# BL602 register map
Vendor: bouffalolab; Series: WiFi BT
Registers are 32-bit, read-write, reset 0x0 unless marked. A register's access mark holds for its fields unless they carry their own. Offsets are from the block's base; [hi:lo] are bit positions; {n}, {i} and the like mark numbered series; 'fields as' and 'values as' point back to an identical list; <NAME> marks a mode.

## GLB — Global register
Base 0x40000000
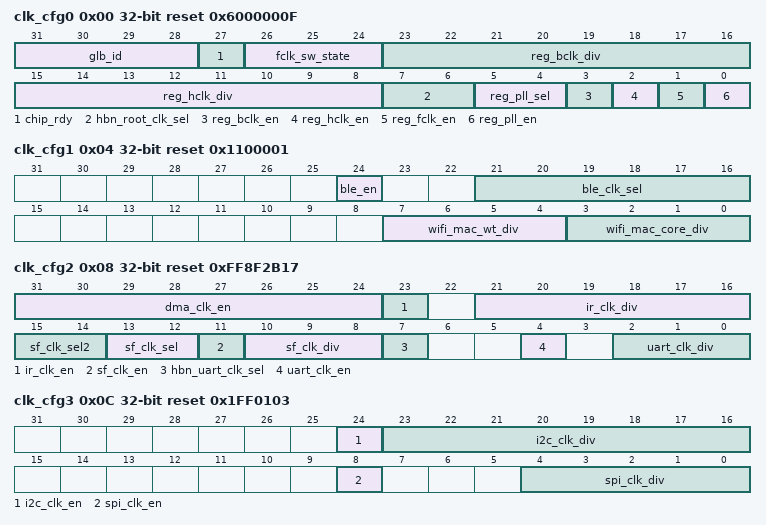
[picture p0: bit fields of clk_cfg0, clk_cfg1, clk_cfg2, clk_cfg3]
0x00 clk_cfg0 reset 0x6000000F — Clock configuration for processor and bus
  [31:28] glb_id ro
  [27] chip_rdy ro
  [26:24] fclk_sw_state ro
  [23:16] reg_bclk_div — Base clock divider
  [15:8] reg_hclk_div — MCU clock divider
  [7:6] hbn_root_clk_sel ro
  [5:4] reg_pll_sel — PLL clock selection (0: 48MHz, 1: 120MHz, 2: 160MHz and 3: 192MHz)
  [3] reg_bclk_en — Base clock enable
  [2] reg_hclk_en — MCU clock enable
  [1] reg_fclk_en
  [0] reg_pll_en — PLL enable
0x04 clk_cfg1 reset 0x1100001
  [24] ble_en — Bluetooth clock enable
  [21:16] ble_clk_sel
  [7:4] wifi_mac_wt_div — WiFi encryption clock divider
  [3:0] wifi_mac_core_div — WiFi core clock divider (0: 80MHz, 1: 40MHz)
0x08 clk_cfg2 reset 0xFF8F2B17 — Clock configuration for UART and Flash
  [31:24] dma_clk_en, [23] ir_clk_en, [21:16] ir_clk_div, [15:14] sf_clk_sel2, [13:12] sf_clk_sel, [11] sf_clk_en, [10:8] sf_clk_div, [7] hbn_uart_clk_sel ro, [4] uart_clk_en, [2:0] uart_clk_div
0x0C clk_cfg3 reset 0x1FF0103 — Clock configuration for I2C and SPI
  [24] i2c_clk_en, [23:16] i2c_clk_div, [8] spi_clk_en, [4:0] spi_clk_div
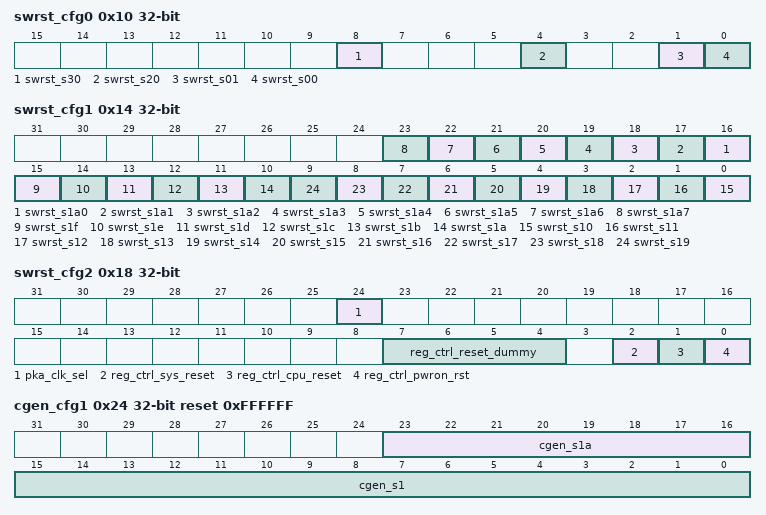
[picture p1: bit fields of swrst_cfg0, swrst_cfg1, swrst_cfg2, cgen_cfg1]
0x10 swrst_cfg0
  [8] swrst_s30, [4] swrst_s20, [1] swrst_s01, [0] swrst_s00
0x14 swrst_cfg1
  [n+16] swrst_s1a{n} (n=0..7), [15] swrst_s1f, [14] swrst_s1e, [13] swrst_s1d, [12] swrst_s1c, [11] swrst_s1b, [10] swrst_s1a, [n-10] swrst_s{n} (n=10..19)
0x18 swrst_cfg2
  [24] pka_clk_sel, [7:4] reg_ctrl_reset_dummy, [2] reg_ctrl_sys_reset, [1] reg_ctrl_cpu_reset, [0] reg_ctrl_pwron_rst
0x1C swrst_cfg3
0x20 cgen_cfg0 reset 0xFF
  [7:0] cgen_m
0x24 cgen_cfg1 reset 0xFFFFFF
  [23:16] cgen_s1a, [15:0] cgen_s1
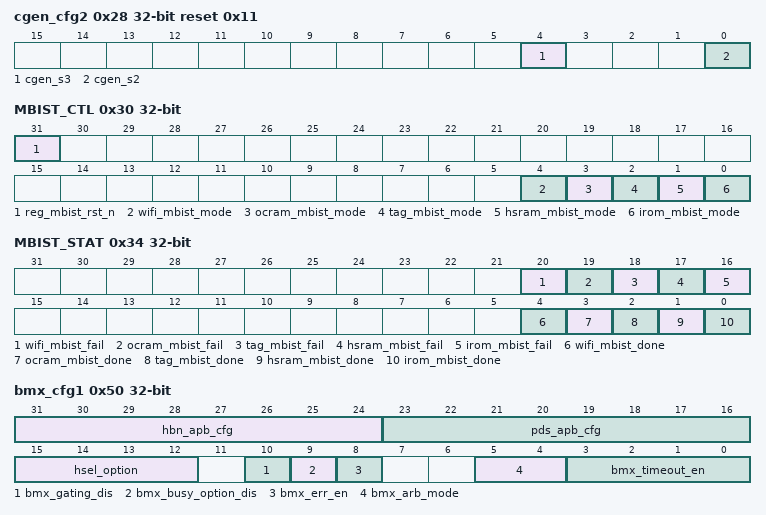
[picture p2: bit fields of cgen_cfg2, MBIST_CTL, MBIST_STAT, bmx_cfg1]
0x28 cgen_cfg2 reset 0x11
  [4] cgen_s3, [0] cgen_s2
0x2C cgen_cfg3
0x30 MBIST_CTL
  [31] reg_mbist_rst_n, [4] wifi_mbist_mode, [3] ocram_mbist_mode, [2] tag_mbist_mode, [1] hsram_mbist_mode, [0] irom_mbist_mode
0x34 MBIST_STAT ro
  [20] wifi_mbist_fail, [19] ocram_mbist_fail, [18] tag_mbist_fail, [17] hsram_mbist_fail, [16] irom_mbist_fail, [4] wifi_mbist_done, [3] ocram_mbist_done, [2] tag_mbist_done, [1] hsram_mbist_done, [0] irom_mbist_done
0x50 bmx_cfg1
  [31:24] hbn_apb_cfg, [23:16] pds_apb_cfg, [15:12] hsel_option, [10] bmx_gating_dis, [9] bmx_busy_option_dis, [8] bmx_err_en, [5:4] bmx_arb_mode, [3:0] bmx_timeout_en
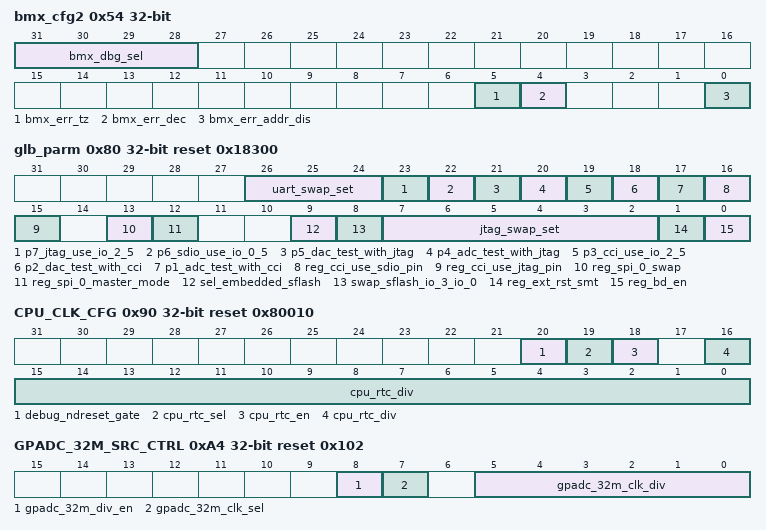
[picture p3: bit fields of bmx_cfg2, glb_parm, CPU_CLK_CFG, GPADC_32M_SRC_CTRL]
0x54 bmx_cfg2
  [31:28] bmx_dbg_sel
  [5] bmx_err_tz ro
  [4] bmx_err_dec ro
  [0] bmx_err_addr_dis — BMX address monitor disable
0x58 bmx_err_addr ro
0x5C bmx_dbg_out ro
{0x60+4i} rsv{i} (i=0..3)
0x70 sram_ret
  [31:0] reg_sram_ret
0x74 sram_slp
  [31:0] reg_sram_slp
0x78 sram_parm reset 0xC0C0C0C
  [31:0] reg_sram_parm
0x7C seam_misc reset 0x3
  [3:0] em_sel
0x80 glb_parm reset 0x18300
  [26:24] uart_swap_set, [23] p7_jtag_use_io_2_5, [22] p6_sdio_use_io_0_5, [21] p5_dac_test_with_jtag, [20] p4_adc_test_with_jtag, [19] p3_cci_use_io_2_5, [18] p2_dac_test_with_cci, [17] p1_adc_test_with_cci, [16] reg_cci_use_sdio_pin, [15] reg_cci_use_jtag_pin, [13] reg_spi_0_swap, [12] reg_spi_0_master_mode, [9] sel_embedded_sflash, [8] swap_sflash_io_3_io_0, [7:2] jtag_swap_set, [1] reg_ext_rst_smt, [0] reg_bd_en
0x90 CPU_CLK_CFG reset 0x80010
  [20] debug_ndreset_gate, [19] cpu_rtc_sel, [18] cpu_rtc_en, [16:0] cpu_rtc_div
0xA4 GPADC_32M_SRC_CTRL reset 0x102 — Clock configuration for GPADC
  [8] gpadc_32m_div_en, [7] gpadc_32m_clk_sel, [5:0] gpadc_32m_clk_div
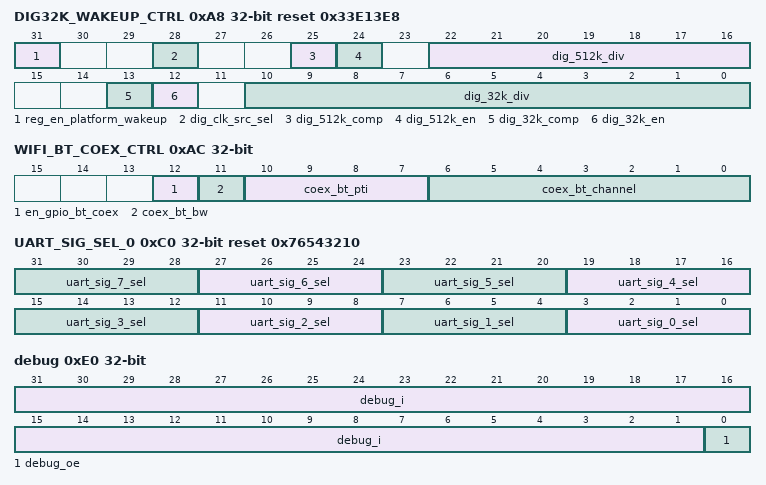
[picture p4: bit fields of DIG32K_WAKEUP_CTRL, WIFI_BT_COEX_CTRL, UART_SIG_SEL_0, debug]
0xA8 DIG32K_WAKEUP_CTRL reset 0x33E13E8
  [31] reg_en_platform_wakeup, [28] dig_clk_src_sel, [25] dig_512k_comp, [24] dig_512k_en, [22:16] dig_512k_div, [13] dig_32k_comp, [12] dig_32k_en, [10:0] dig_32k_div
0xAC WIFI_BT_COEX_CTRL
  [12] en_gpio_bt_coex, [11] coex_bt_bw, [10:7] coex_bt_pti, [6:0] coex_bt_channel
0xC0 UART_SIG_SEL_0 reset 0x76543210
  [4n+3:4n] uart_sig_{n}_sel (n=0..7)
0xD0 DBG_SEL_LL
  [31:0] reg_dbg_ll_ctrl
0xD4 DBG_SEL_LH
  [31:0] reg_dbg_lh_ctrl
0xD8 DBG_SEL_HL
  [31:0] reg_dbg_hl_ctrl
0xDC DBG_SEL_HH
  [31:0] reg_dbg_hh_ctrl
0xE0 debug
  [31:1] debug_i ro, [0] debug_oe
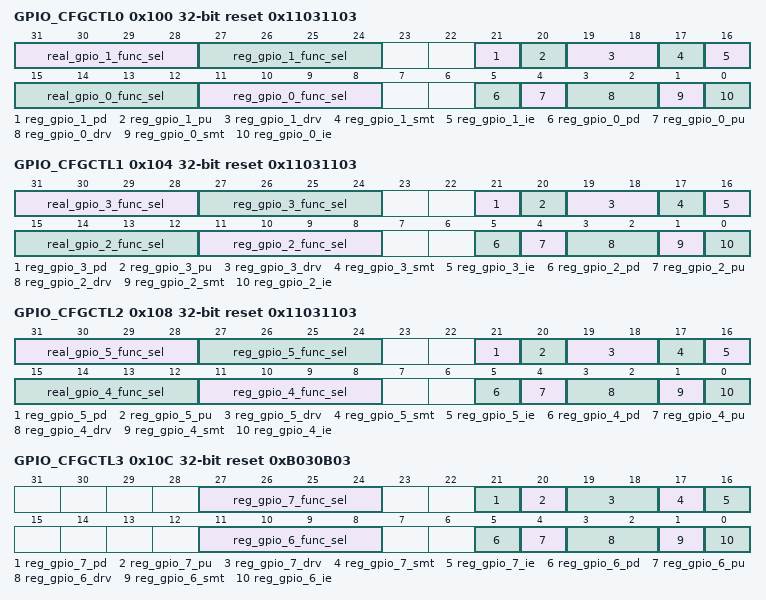
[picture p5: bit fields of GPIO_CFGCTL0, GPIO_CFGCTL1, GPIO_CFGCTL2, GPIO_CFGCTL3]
0x100 GPIO_CFGCTL0 reset 0x11031103 — GPIO0, GPIO1 configuration
  [31:28] real_gpio_1_func_sel ro
    0=GLB_GPIO_REAL_MODE_REG (Function select is reg_gpio_1_func_sel); 1=GLB_GPIO_REAL_MODE_SDIO; 12=GLB_GPIO_REAL_MODE_RF; 14=GLB_GPIO_REAL_MODE_JTAG; 15=GLB_GPIO_REAL_MODE_CCI
  [27:24] reg_gpio_1_func_sel — Function select for GPIO1.
    1=SDIO_CMD; 2=SF_D2; 4=SPI_MOSI_SPI_MISO; 6=I2C_SDA; 7=UART_SIG1; 8=PWM_CH1; 9=FEM_GPIO_1; 10=ATEST_IP; 11=SWGPIO_1; 14=E21_TDI
  [21] reg_gpio_1_pd — Pull Down Resistor for GPIO1.
    0=disabled; 1=enabled
  [20] reg_gpio_1_pu — Pull Up Resistor for GPIO1.
    0=disabled; 1=enabled
  [19:18] reg_gpio_1_drv — Driving control enabled for GPIO1.
    0=disabled; 1=enabled
  [17] reg_gpio_1_smt — Schmitt trigger enabled for GPIO1.
    0=disabled; 1=enabled
  [16] reg_gpio_1_ie — Input enable for GPIO1.
    0=disabled; 1=enabled
  [15:12] real_gpio_0_func_sel ro
    0=GLB_GPIO_REAL_MODE_REG (Function select is reg_gpio_0_func_sel); 1=GLB_GPIO_REAL_MODE_SDIO; 12=GLB_GPIO_REAL_MODE_RF; 14=GLB_GPIO_REAL_MODE_JTAG; 15=GLB_GPIO_REAL_MODE_CCI
  [11:8] reg_gpio_0_func_sel — Function select for GPIO0.
    1=SDIO_CLK; 2=SF_D1; 4=SPI_MOSI_SPI_MISO; 6=I2C_SCL; 7=UART_SIG0; 8=PWM_CH0; 9=FEM_GPIO_0; 10=ATEST_IN; 11=SWGPIO_0; 14=E21_TMS
  [5] reg_gpio_0_pd — Pull Down Resistor for GPIO0.
    0=disabled; 1=enabled
  [4] reg_gpio_0_pu — Pull Up Resistor for GPIO0.
    0=disabled; 1=enabled
  [3:2] reg_gpio_0_drv — Driving control for GPIO0.
    0=disabled; 1=enabled
  [1] reg_gpio_0_smt — Schmitt trigger enabled for GPIO0.
    0=disabled; 1=enabled
  [0] reg_gpio_0_ie — GPIO0 input enable.
    0=disabled; 1=enabled
0x104 GPIO_CFGCTL1 reset 0x11031103 — GPIO2, GPIO3 configuration
  [31:28] real_gpio_3_func_sel ro
    0=GLB_GPIO_REAL_MODE_REG (Function select is reg_gpio_3_func_sel); 1=GLB_GPIO_REAL_MODE_SDIO; 12=GLB_GPIO_REAL_MODE_RF; 14=GLB_GPIO_REAL_MODE_JTAG; 15=GLB_GPIO_REAL_MODE_CCI
  [27:24] reg_gpio_3_func_sel — Function select for GPIO3.
    1=SDIO_DAT1; 4=SPI_SCLK; 6=I2C_SDA; 7=UART_SIG3; 8=PWM_CH3; 9=FEM_GPIO_3; 10=ATEST_QP; 11=SWGPIO_3; 14=E21_TDO
  [21] reg_gpio_3_pd — Pull Down Resistor for GPIO3.
    0=disabled; 1=enabled
  [20] reg_gpio_3_pu — Pull Up Resistor for GPIO3.
    0=disabled; 1=enabled
  [19:18] reg_gpio_3_drv — Driving control enabled for GPIO3.
    0=disabled; 1=enabled
  [17] reg_gpio_3_smt — Schmitt trigger enabled for GPIO3.
    0=disabled; 1=enabled
  [16] reg_gpio_3_ie — Input enable for GPIO3.
    0=disabled; 1=enabled
  [15:12] real_gpio_2_func_sel ro
    0=GLB_GPIO_REAL_MODE_REG (Function select is reg_gpio_2_func_sel); 1=GLB_GPIO_REAL_MODE_SDIO; 12=GLB_GPIO_REAL_MODE_RF; 14=GLB_GPIO_REAL_MODE_JTAG; 15=GLB_GPIO_REAL_MODE_CCI
  [11:8] reg_gpio_2_func_sel — Function select for GPIO2.
    1=SDIO_DAT0; 2=SF_D3; 4=SPI_SS; 6=I2C_SCL; 7=UART_SIG2; 8=PWM_CH2; 9=FEM_GPIO_2; 10=ATEST_QN; 11=SWGPIO_2; 14=E21_TCK
  [5] reg_gpio_2_pd — Pull Down Resistor for GPIO2.
    0=disabled; 1=enabled
  [4] reg_gpio_2_pu — Pull Up Resistor for GPIO2.
    0=disabled; 1=enabled
  [3:2] reg_gpio_2_drv — Driving control enabled for GPIO2.
    0=disabled; 1=enabled
  [1] reg_gpio_2_smt — Schmitt trigger enabled for GPIO2.
    0=disabled; 1=enabled
  [0] reg_gpio_2_ie — Input enable for GPIO2.
    0=disabled; 1=enabled
0x108 GPIO_CFGCTL2 reset 0x11031103 — GPIO4, GPIO5 configuration
  [31:28] real_gpio_5_func_sel ro
    0=GLB_GPIO_REAL_MODE_REG (Function select is reg_gpio_5_func_sel); 1=GLB_GPIO_REAL_MODE_SDIO; 12=GLB_GPIO_REAL_MODE_RF; 14=GLB_GPIO_REAL_MODE_JTAG; 15=GLB_GPIO_REAL_MODE_CCI
  [27:24] reg_gpio_5_func_sel — Function select for GPIO5.
    1=SDIO_DAT3; 4=SPI_MOSI_SPI_MISO; 6=I2C_SDA; 7=UART_SIG5; 8=PWM_CH0; 9=FEM_GPIO_1; 10=GPIP_CH4; 11=SWGPIO_5; 14=E21_TDI
  [21] reg_gpio_5_pd — Pull Down Resistor for GPIO5.
    0=disabled; 1=enabled
  [20] reg_gpio_5_pu — Pull Up Resistor for GPIO5.
    0=disabled; 1=enabled
  [19:18] reg_gpio_5_drv — Driving control enabled for GPIO5.
    0=disabled; 1=enabled
  [17] reg_gpio_5_smt — Schmitt trigger enabled for GPIO5.
    0=disabled; 1=enabled
  [16] reg_gpio_5_ie — Input enable for GPIO5.
    0=disabled; 1=enabled
  [15:12] real_gpio_4_func_sel ro
    0=GLB_GPIO_REAL_MODE_REG (Function select is reg_gpio_4_func_sel); 1=GLB_GPIO_REAL_MODE_SDIO; 12=GLB_GPIO_REAL_MODE_RF; 14=GLB_GPIO_REAL_MODE_JTAG; 15=GLB_GPIO_REAL_MODE_CCI
  [11:8] reg_gpio_4_func_sel — Function select for GPIO4.
    1=SDIO_DAT2; 4=SPI_MISO_SPI_MOSI; 6=I2C_SCL; 7=UART_SIG4; 8=PWM_CH4; 9=FEM_GPIO_0; 10=GPIP_CH1; 11=SWGPIO_4; 14=E21_TMS
  [5] reg_gpio_4_pd — Pull Down Resistor for GPIO4.
    0=disabled; 1=enabled
  [4] reg_gpio_4_pu — Pull Up Resistor for GPIO4.
    0=disabled; 1=enabled
  [3:2] reg_gpio_4_drv — Driving control enabled for GPIO4.
    0=disabled; 1=enabled
  [1] reg_gpio_4_smt — Schmitt trigger enabled for GPIO4.
    0=disabled; 1=enabled
  [0] reg_gpio_4_ie — Input enable for GPIO4.
    0=disabled; 1=enabled
0x10C GPIO_CFGCTL3 reset 0xB030B03 — GPIO6, GPIO7 configuration
  [27:24] reg_gpio_7_func_sel — Function select for GPIO7.
    4=SPI_SCLK; 6=I2C_SDA; 7=UART_SIG7; 8=PWM_CH2; 9=FEM_GPIO_3; 11=SWGPIO_7; 14=E21_TDO
  [21] reg_gpio_7_pd — Pull Down Resistor for GPIO7.
    0=disabled; 1=enabled
  [20] reg_gpio_7_pu — Pull Up Resistor for GPIO7.
    0=disabled; 1=enabled
  [19:18] reg_gpio_7_drv — Driving control enabled for GPIO7.
    0=disabled; 1=enabled
  [17] reg_gpio_7_smt — Schmitt trigger enabled for GPIO7.
    0=disabled; 1=enabled
  [16] reg_gpio_7_ie — Input enable for GPIO7.
    0=disabled; 1=enabled
  [11:8] reg_gpio_6_func_sel — Function select for GPIO6.
    4=SPI_SS; 6=I2C_SCL; 7=UART_SIG6; 8=PWM_CH1; 9=FEM_GPIO_2; 10=GPIP_CH5; 11=SWGPIO_6; 14=E21_TCK
  [5] reg_gpio_6_pd — Pull Down Resistor for GPIO6.
    0=disabled; 1=enabled
  [4] reg_gpio_6_pu — Pull Up Resistor for GPIO6.
    0=disabled; 1=enabled
  [3:2] reg_gpio_6_drv — Driving control enabled for GPIO6.
    0=disabled; 1=enabled
  [1] reg_gpio_6_smt — Schmitt trigger enabled for GPIO6.
    0=disabled; 1=enabled
  [0] reg_gpio_6_ie — Input enable for GPIO6.
    0=disabled; 1=enabled
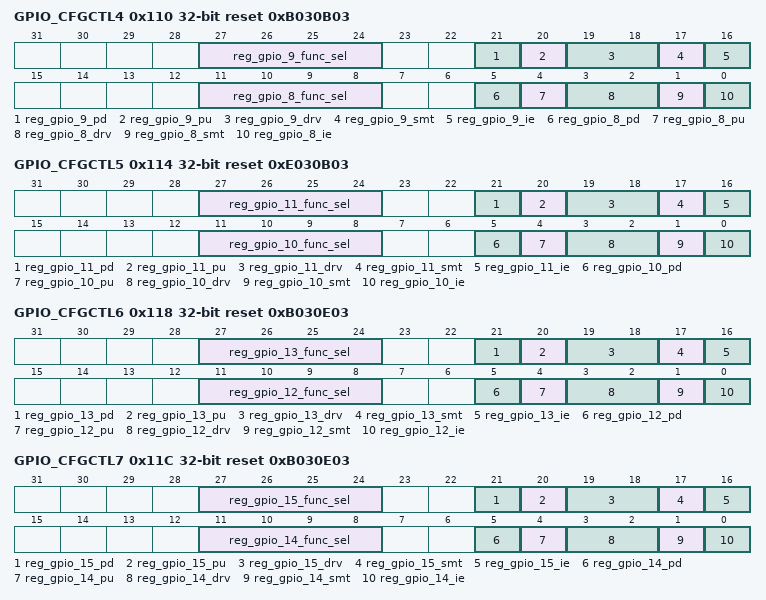
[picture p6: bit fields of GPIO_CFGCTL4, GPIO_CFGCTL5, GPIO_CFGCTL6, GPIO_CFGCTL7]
0x110 GPIO_CFGCTL4 reset 0xB030B03 — GPIO8, GPIO9 configuration
  [27:24] reg_gpio_9_func_sel — Function select for GPIO9.
    4=SPI_MOSI_SPI_MISO; 6=I2C_SDA; 7=UART_SIG1; 8=PWM_CH4; 9=FEM_GPIO_1; 10=GPIP_CH6_GPIP_CH7; 11=SWGPIO_9; 14=E21_TDI
  [21] reg_gpio_9_pd — Pull Down Resistor for GPIO9.
    0=disabled; 1=enabled
  [20] reg_gpio_9_pu — Pull Up Resistor for GPIO9.
    0=disabled; 1=enabled
  [19:18] reg_gpio_9_drv — Driving control enabled for GPIO9.
    0=disabled; 1=enabled
  [17] reg_gpio_9_smt — Schmitt trigger enabled for GPIO9.
    0=disabled; 1=enabled
  [16] reg_gpio_9_ie — Input enable for GPIO9.
    0=disabled; 1=enabled
  [11:8] reg_gpio_8_func_sel — Function select for GPIO8.
    4=SPI_MISO_SPI_MOSI; 6=I2C_SCL; 7=UART_SIG0; 8=PWM_CH3; 9=FEM_GPIO_0; 11=SWGPIO_8; 14=E21_TMS
  [5] reg_gpio_8_pd — Pull Down Resistor for GPIO8.
    0=disabled; 1=enabled
  [4] reg_gpio_8_pu — Pull Up Resistor for GPIO8.
    0=disabled; 1=enabled
  [3:2] reg_gpio_8_drv — Driving control enabled for GPIO8.
    0=disabled; 1=enabled
  [1] reg_gpio_8_smt — Schmitt trigger enabled for GPIO8.
    0=disabled; 1=enabled
  [0] reg_gpio_8_ie — Input enable for GPIO8.
    0=disabled; 1=enabled
0x114 GPIO_CFGCTL5 reset 0xE030B03 — GPIO10, GPIO11 configuration
  [27:24] reg_gpio_11_func_sel — Function select for GPIO11.
    4=SPI_SCLK; 6=I2C_SDA; 7=UART_SIG3; 8=PWM_CH1; 9=FEM_GPIO_3; 10=IRLED_OUT_GPIP_CH10; 11=SWGPIO_11; 14=E21_TDO
  [21] reg_gpio_11_pd — Pull Down Resistor for GPIO11.
    0=disabled; 1=enabled
  [20] reg_gpio_11_pu — Pull Up Resistor for GPIO11.
    0=disabled; 1=enabled
  [19:18] reg_gpio_11_drv — Driving control enabled for GPIO11.
    0=disabled; 1=enabled
  [17] reg_gpio_11_smt — Schmitt trigger enabled for GPIO11.
    0=disabled; 1=enabled
  [16] reg_gpio_11_ie — Input enable for GPIO11.
    0=disabled; 1=enabled
  [11:8] reg_gpio_10_func_sel — Function select for GPIO10.
    4=SPI_SS; 6=I2C_SCL; 7=UART_SIG2; 8=PWM_CH0; 9=FEM_GPIO_2; 10=MICBIAS_GPIP_CH8_GPIP_CH9; 11=SWGPIO_10; 14=E21_TCK
  [5] reg_gpio_10_pd — Pull Down Resistor for GPIO10.
    0=disabled; 1=enabled
  [4] reg_gpio_10_pu — Pull Up Resistor for GPIO10.
    0=disabled; 1=enabled
  [3:2] reg_gpio_10_drv — Driving control enabled for GPIO10.
    0=disabled; 1=enabled
  [1] reg_gpio_10_smt — Schmitt trigger enabled for GPIO10.
    0=disabled; 1=enabled
  [0] reg_gpio_10_ie — Input enable for GPIO10.
    0=disabled; 1=enabled
0x118 GPIO_CFGCTL6 reset 0xB030E03 — GPIO12, GPIO13 configuration
  [27:24] reg_gpio_13_func_sel — Function select for GPIO13.
    4=SPI_MOSI_SPI_MISO; 6=I2C_SDA; 7=UART_SIG5; 8=PWM_CH3; 9=FEM_GPIO_1; 10=GPIP_CH3; 11=SWGPIO_13; 14=E21_TDI
  [21] reg_gpio_13_pd — Pull Down Resistor for GPIO13.
    0=disabled; 1=enabled
  [20] reg_gpio_13_pu — Pull Up Resistor for GPIO13.
    0=disabled; 1=enabled
  [19:18] reg_gpio_13_drv — Driving control enabled for GPIO13.
    0=disabled; 1=enabled
  [17] reg_gpio_13_smt — Schmitt trigger enabled for GPIO13.
    0=disabled; 1=enabled
  [16] reg_gpio_13_ie — Input enable for GPIO13.
    0=disabled; 1=enabled
  [11:8] reg_gpio_12_func_sel — Function select for GPIO12.
    4=SPI_MISO_SPI_MOSI; 6=I2C_SCL; 7=UART_SIG4; 8=PWM_CH2; 9=FEM_GPIO_0; 10=GPIP_CH0_GPADC_VREF_EXT; 11=SWGPIO_12; 14=E21_TMS
  [5] reg_gpio_12_pd — Pull Down Resistor for GPIO12.
    0=disabled; 1=enabled
  [4] reg_gpio_12_pu — Pull Up Resistor for GPIO12.
    0=disabled; 1=enabled
  [3:2] reg_gpio_12_drv — Driving control enabled for GPIO12.
    0=disabled; 1=enabled
  [1] reg_gpio_12_smt — Schmitt trigger enabled for GPIO12.
    0=disabled; 1=enabled
  [0] reg_gpio_12_ie — Input enable for GPIO12.
    0=disabled; 1=enabled
0x11C GPIO_CFGCTL7 reset 0xB030E03 — GPIO14, GPIO15 configuration
  [27:24] reg_gpio_15_func_sel — Function select for GPIO15.
    4=SPI_SCLK; 6=I2C_SDA; 7=UART_SIG7; 8=PWM_CH0; 9=FEM_GPIO_3; 10=PSW_IRRCV_OUT_GPIP_CH11; 11=SWGPIO_15; 14=E21_TDO
  [21] reg_gpio_15_pd — Pull Down Resistor for GPIO15.
    0=disabled; 1=enabled
  [20] reg_gpio_15_pu — Pull Up Resistor for GPIO15.
    0=disabled; 1=enabled
  [19:18] reg_gpio_15_drv — Driving control enabled for GPIO15.
    0=disabled; 1=enabled
  [17] reg_gpio_15_smt — Schmitt trigger enabled for GPIO15.
    0=disabled; 1=enabled
  [16] reg_gpio_15_ie — Input enable for GPIO15.
    0=disabled; 1=enabled
  [11:8] reg_gpio_14_func_sel — Function select for GPIO14.
    4=SPI_SS; 6=I2C_SCL; 7=UART_SIG6; 8=PWM_CH4; 9=FEM_GPIO_2; 10=GPIP_CH2; 11=SWGPIO_14; 14=E21_TCK
  [5] reg_gpio_14_pd — Pull Down Resistor for GPIO14.
    0=disabled; 1=enabled
  [4] reg_gpio_14_pu — Pull Up Resistor for GPIO14.
    0=disabled; 1=enabled
  [3:2] reg_gpio_14_drv — Driving control enabled for GPIO14.
    0=disabled; 1=enabled
  [1] reg_gpio_14_smt — Schmitt trigger enabled for GPIO14.
    0=disabled; 1=enabled
  [0] reg_gpio_14_ie — Input enable for GPIO14.
    0=disabled; 1=enabled
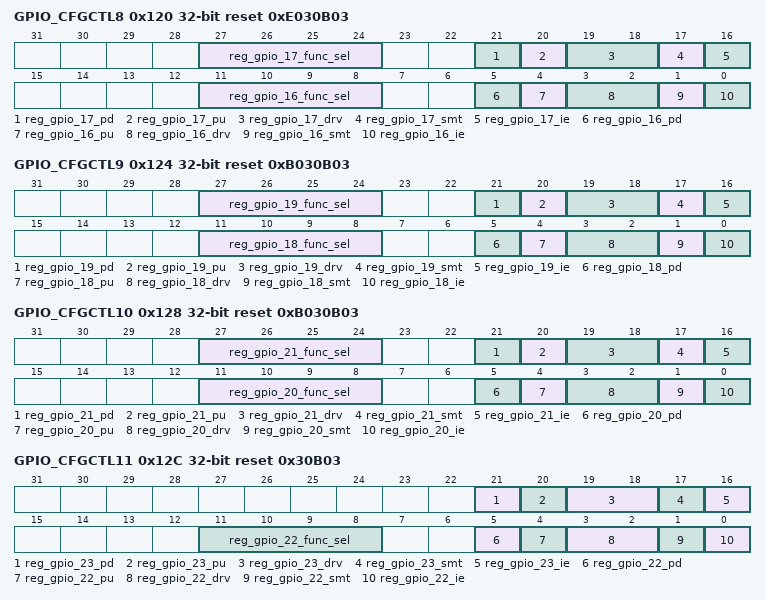
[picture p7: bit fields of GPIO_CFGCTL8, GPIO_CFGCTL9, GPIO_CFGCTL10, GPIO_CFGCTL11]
0x120 GPIO_CFGCTL8 reset 0xE030B03 — GPIO16, GPIO17 configuration
  [27:24] reg_gpio_17_func_sel — Function select for GPIO17.
    2=SF_D3; 4=SPI_MOSI_SPI_MISO; 6=I2C_SDA; 7=UART_SIG1; 8=PWM_CH2; 9=FEM_GPIO_1; 10=PMIP_DC_TP_OUT; 11=SWGPIO_17; 14=E21_TDI
  [21] reg_gpio_17_pd — Pull Down Resistor for GPIO17.
    0=disabled; 1=enabled
  [20] reg_gpio_17_pu — Pull Up Resistor for GPIO17.
    0=disabled; 1=enabled
  [19:18] reg_gpio_17_drv — Driving control enabled for GPIO17.
    0=disabled; 1=enabled
  [17] reg_gpio_17_smt — Schmitt trigger enabled for GPIO17.
    0=disabled; 1=enabled
  [16] reg_gpio_17_ie — Input enable for GPIO17.
    0=disabled; 1=enabled
  [11:8] reg_gpio_16_func_sel — Function select for GPIO16.
    4=SPI_MISO_SPI_MOSI; 6=I2C_SCL; 7=UART_SIG0; 8=PWM_CH1; 9=FEM_GPIO_0; 11=SWGPIO_16; 14=E21_TMS
  [5] reg_gpio_16_pd — Pull Down Resistor for GPIO16.
    0=disabled; 1=enabled
  [4] reg_gpio_16_pu — Pull Up Resistor for GPIO16.
    0=disabled; 1=enabled
  [3:2] reg_gpio_16_drv — Driving control enabled for GPIO16.
    0=disabled; 1=enabled
  [1] reg_gpio_16_smt — Schmitt trigger enabled for GPIO16.
    0=disabled; 1=enabled
  [0] reg_gpio_16_ie — Input enable for GPIO16.
    0=disabled; 1=enabled
0x124 GPIO_CFGCTL9 reset 0xB030B03 — GPIO18, GPIO19 configuration
  [27:24] reg_gpio_19_func_sel — Function select for GPIO19.
    2=SF_D1; 4=SPI_SCLK; 6=I2C_SDA; 7=UART_SIG3; 8=PWM_CH4; 9=FEM_GPIO_3; 11=SWGPIO_19; 14=E21_TDO
  [21] reg_gpio_19_pd — Pull Down Resistor for GPIO19.
    0=disabled; 1=enabled
  [20] reg_gpio_19_pu — Pull Up Resistor for GPIO19.
    0=disabled; 1=enabled
  [19:18] reg_gpio_19_drv — Driving control enabled for GPIO19.
    0=disabled; 1=enabled
  [17] reg_gpio_19_smt — Schmitt trigger enabled for GPIO19.
    0=disabled; 1=enabled
  [16] reg_gpio_19_ie — Input enable for GPIO19.
    0=disabled; 1=enabled
  [11:8] reg_gpio_18_func_sel — Function select for GPIO18.
    2=SF_D2; 4=SPI_SS; 6=I2C_SCL; 7=UART_SIG2; 8=PWM_CH3; 9=FEM_GPIO_2; 11=SWGPIO_18; 14=E21_TCK
  [5] reg_gpio_18_pd — Pull Down Resistor for GPIO18.
    0=disabled; 1=enabled
  [4] reg_gpio_18_pu — Pull Up Resistor for GPIO18.
    0=disabled; 1=enabled
  [3:2] reg_gpio_18_drv — Driving control enabled for GPIO18.
    0=disabled; 1=enabled
  [1] reg_gpio_18_smt — Schmitt trigger enabled for GPIO18.
    0=disabled; 1=enabled
  [0] reg_gpio_18_ie — Input enable for GPIO18.
    0=disabled; 1=enabled
0x128 GPIO_CFGCTL10 reset 0xB030B03 — GPIO20, GPIO21 configuration
  [27:24] reg_gpio_21_func_sel — Function select for GPIO21.
    2=SF_CS; 4=SPI_MOSI_SPI_MISO; 6=I2C_SDA; 7=UART_SIG5; 8=PWM_CH1; 9=FEM_GPIO_1; 11=SWGPIO_21; 14=E21_TDI
  [21] reg_gpio_21_pd — Pull Down Resistor for GPIO21.
    0=disabled; 1=enabled
  [20] reg_gpio_21_pu — Pull Up Resistor for GPIO21.
    0=disabled; 1=enabled
  [19:18] reg_gpio_21_drv — Driving control enabled for GPIO21.
    0=disabled; 1=enabled
  [17] reg_gpio_21_smt — Schmitt trigger enabled for GPIO21.
    0=disabled; 1=enabled
  [16] reg_gpio_21_ie — Input enable for GPIO21.
    0=disabled; 1=enabled
  [11:8] reg_gpio_20_func_sel — Function select for GPIO20.
    2=SF_D0; 4=SPI_MISO_SPI_MOSI; 6=I2C_SCL; 7=UART_SIG4; 8=PWM_CH0; 9=FEM_GPIO_0; 11=SWGPIO_20; 14=E21_TMS
  [5] reg_gpio_20_pd — Pull Down Resistor for GPIO20.
    0=disabled; 1=enabled
  [4] reg_gpio_20_pu — Pull Up Resistor for GPIO20.
    0=disabled; 1=enabled
  [3:2] reg_gpio_20_drv — Driving control enabled for GPIO20.
    0=disabled; 1=enabled
  [1] reg_gpio_20_smt — Schmitt trigger enabled for GPIO20.
    0=disabled; 1=enabled
  [0] reg_gpio_20_ie — Input enable for GPIO20.
    0=disabled; 1=enabled
0x12C GPIO_CFGCTL11 reset 0x30B03 — GPIO22, GPIO23 configuration
  [21] reg_gpio_23_pd — Pull Down Resistor for GPIO23.
    0=disabled; 1=enabled
  [20] reg_gpio_23_pu — Pull Up Resistor for GPIO23.
    0=disabled; 1=enabled
  [19:18] reg_gpio_23_drv — Driving control enabled for GPIO23.
    0=disabled; 1=enabled
  [17] reg_gpio_23_smt — Schmitt trigger enabled for GPIO23.
    0=disabled; 1=enabled
  [16] reg_gpio_23_ie — Input enable for GPIO23.
    0=disabled; 1=enabled
  [11:8] reg_gpio_22_func_sel — Function select for GPIO22.
    2=SF_CLK_OUT; 4=SPI_SS; 6=I2C_SCL; 7=UART_SIG6; 8=PWM_CH2; 9=FEM_GPIO_2; 11=SWGPIO_22; 14=E21_TCK
  [5] reg_gpio_22_pd — Pull Down Resistor for GPIO22.
    0=disabled; 1=enabled
  [4] reg_gpio_22_pu — Pull Up Resistor for GPIO22.
    0=disabled; 1=enabled
  [3:2] reg_gpio_22_drv — Driving control enabled for GPIO22.
    0=disabled; 1=enabled
  [1] reg_gpio_22_smt — Schmitt trigger enabled for GPIO22.
    0=disabled; 1=enabled
  [0] reg_gpio_22_ie — Input enable for GPIO22.
    0=disabled; 1=enabled
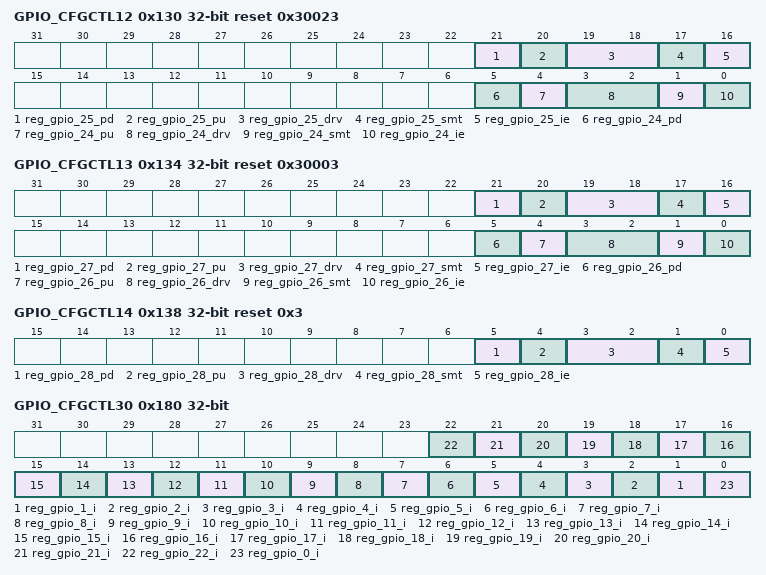
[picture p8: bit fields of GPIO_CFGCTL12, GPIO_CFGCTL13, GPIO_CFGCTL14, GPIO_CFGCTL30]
0x130 GPIO_CFGCTL12 reset 0x30023 — GPIO24, GPIO25 configuration
  [all] fields
    0=disabled; 1=enabled
  [21] reg_gpio_25_pd — Pull Down Resistor for GPIO25.
  [20] reg_gpio_25_pu — Pull Up Resistor for GPIO25.
  [19:18] reg_gpio_25_drv — Driving control enabled for GPIO25.
  [17] reg_gpio_25_smt — Schmitt trigger enabled for GPIO25.
  [16] reg_gpio_25_ie — Input enable for GPIO25.
  [5] reg_gpio_24_pd — Pull Down Resistor for GPIO24.
  [4] reg_gpio_24_pu — Pull Up Resistor for GPIO24.
  [3:2] reg_gpio_24_drv — Driving control enabled for GPIO24.
  [1] reg_gpio_24_smt — Schmitt trigger enabled for GPIO24.
  [0] reg_gpio_24_ie — Input enable for GPIO24.
0x134 GPIO_CFGCTL13 reset 0x30003 — GPIO26, GPIO27 configuration
  [all] fields
    0=disabled; 1=enabled
  [21] reg_gpio_27_pd — Pull Down Resistor for GPIO27.
  [20] reg_gpio_27_pu — Pull Up Resistor for GPIO27.
  [19:18] reg_gpio_27_drv — Driving control enabled for GPIO27.
  [17] reg_gpio_27_smt — Schmitt trigger enabled for GPIO27.
  [16] reg_gpio_27_ie — Input enable for GPIO27.
  [5] reg_gpio_26_pd — Pull Down Resistor for GPIO26.
  [4] reg_gpio_26_pu — Pull Up Resistor for GPIO26.
  [3:2] reg_gpio_26_drv — Driving control enabled for GPIO26.
  [1] reg_gpio_26_smt — Schmitt trigger enabled for GPIO26.
  [0] reg_gpio_26_ie — Input enable for GPIO26.
0x138 GPIO_CFGCTL14 reset 0x3 — GPIO28 configuration
  [all] fields
    0=disabled; 1=enabled
  [5] reg_gpio_28_pd — Pull Down Resistor for GPIO28.
  [4] reg_gpio_28_pu — Pull Up Resistor for GPIO28.
  [3:2] reg_gpio_28_drv — Driving control enabled for GPIO28.
  [1] reg_gpio_28_smt — Schmitt trigger enabled for GPIO28.
  [0] reg_gpio_28_ie — Input enable for GPIO28.
0x180 GPIO_CFGCTL30 ro — Input register for all GPIO pins. Input Enabled bit must be set in configuration register to work.
  [n] reg_gpio_{n}_i (n=1..22) — Input register for GPIO{n}.
    0=disabled; 1=enabled
  [0] reg_gpio_0_i
0x184 GPIO_CFGCTL31 — Reserved according to SDK.
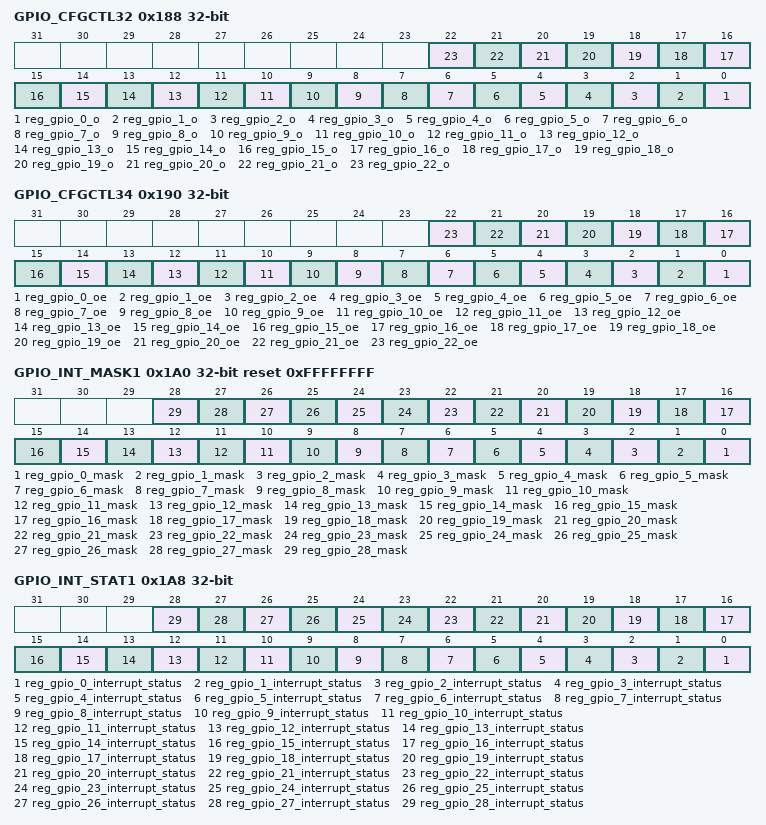
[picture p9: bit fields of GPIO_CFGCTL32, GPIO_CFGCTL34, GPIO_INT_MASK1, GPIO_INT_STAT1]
0x188 GPIO_CFGCTL32 — Output register for all GPIO pins. Output Enabled bit must be set in Output Enable register to work.
  [all] fields
    0=disabled; 1=enabled
  [n] reg_gpio_{n}_o (n=0..22) — Output register for GPIO{n}.
0x18C GPIO_CFGCTL33 — Reserved according to SDK.
0x190 GPIO_CFGCTL34 — Output enable register for GPIO.
  [all] fields
    0=disabled; 1=enabled
  [n] reg_gpio_{n}_oe (n=0..22) — Output enable register for GPIO{n}.
0x194 GPIO_CFGCTL35 — Reserved according to SDK.
0x1A0 GPIO_INT_MASK1 reset 0xFFFFFFFF — Interrupt masking register. The SDK limits the GPIO pins to < 32 although the docs do not mention more than 28 GPIO pins.
  [all] fields
    0=unmasked; 1=masked
  [n] reg_gpio_{n}_mask (n=0..28) — Mask register for GPIO{n}.
0x1A8 GPIO_INT_STAT1 ro — Interrupt status register. The SDK limits the GPIO pins to < 32 although the docs do not mention more than 28 GPIO pins.
  [all] fields
    0=reset; 1=set
  [n] reg_gpio_{n}_interrupt_status (n=0..28) — Interrupt status register for GPIO{n}.
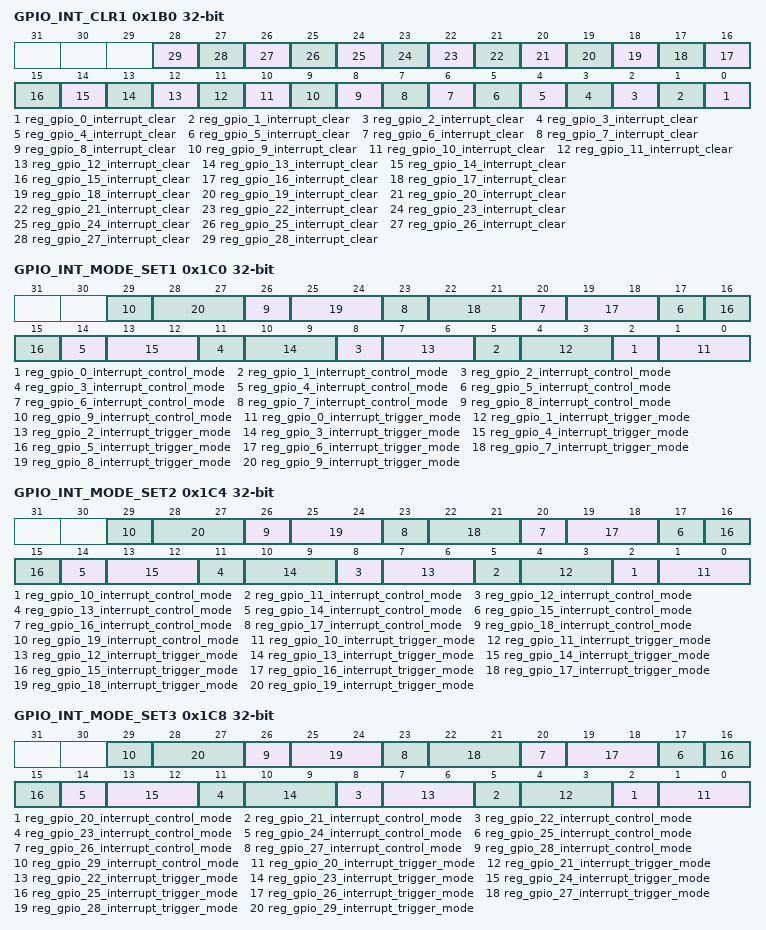
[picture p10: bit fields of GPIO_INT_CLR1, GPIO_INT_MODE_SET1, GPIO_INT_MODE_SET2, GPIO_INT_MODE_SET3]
0x1B0 GPIO_INT_CLR1 — Interrupt clearing register.
  [all] fields
    0=no_clear; 1=clear
  [n] reg_gpio_{n}_interrupt_clear (n=0..28) — Interrupt clearing register for GPIO{n}.
0x1C0 GPIO_INT_MODE_SET1 — GPIO interrupt trigger and control register for GPIO0-GPIO9.
  [3n+2] reg_gpio_{n}_interrupt_control_mode (n=0..9) — Interrupt control mode register for GPIO{n}.
    0=synchronous; 1=asynchronous
  [3n+1:3n] reg_gpio_{n}_interrupt_trigger_mode (n=0..9) — Interrupt trigger mode register for GPIO{n}.
    0=negative_pulse; 1=positive_pulse; 2=negative_level; 3=positive_level
0x1C4 GPIO_INT_MODE_SET2 — GPIO interrupt trigger and control register for GPIO10-GPIO19.
  [3n-28] reg_gpio_{n}_interrupt_control_mode (n=10..19) — Interrupt control mode register for GPIO{n}.
    0=synchronous; 1=asynchronous
  [3n-29:3n-30] reg_gpio_{n}_interrupt_trigger_mode (n=10..19) — Interrupt trigger mode register for GPIO{n}.
    values as GPIO_INT_MODE_SET1.reg_gpio_0_interrupt_trigger_mode
0x1C8 GPIO_INT_MODE_SET3 — GPIO interrupt trigger and control register for GPIO20-GPIO29.
  [3n-58] reg_gpio_{n}_interrupt_control_mode (n=20..29) — Interrupt control mode register for GPIO{n}.
    0=synchronous; 1=asynchronous
  [3n-59:3n-60] reg_gpio_{n}_interrupt_trigger_mode (n=20..29) — Interrupt trigger mode register for GPIO{n}.
    values as GPIO_INT_MODE_SET1.reg_gpio_0_interrupt_trigger_mode
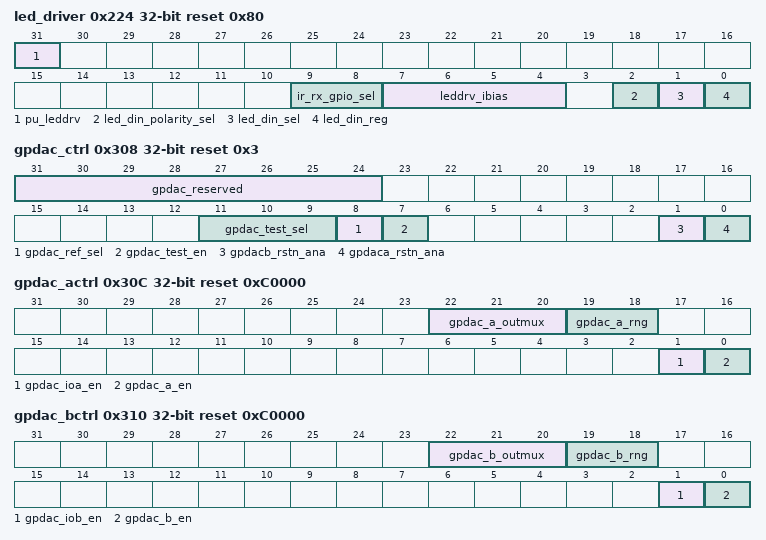
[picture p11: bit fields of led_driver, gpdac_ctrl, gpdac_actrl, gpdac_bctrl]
0x224 led_driver reset 0x80
  [31] pu_leddrv, [9:8] ir_rx_gpio_sel, [7:4] leddrv_ibias, [2] led_din_polarity_sel, [1] led_din_sel, [0] led_din_reg
0x308 gpdac_ctrl reset 0x3
  [31:24] gpdac_reserved, [11:9] gpdac_test_sel, [8] gpdac_ref_sel, [7] gpdac_test_en, [1] gpdacb_rstn_ana, [0] gpdaca_rstn_ana
0x30C gpdac_actrl reset 0xC0000
  [22:20] gpdac_a_outmux, [19:18] gpdac_a_rng, [1] gpdac_ioa_en, [0] gpdac_a_en
0x310 gpdac_bctrl reset 0xC0000
  [22:20] gpdac_b_outmux, [19:18] gpdac_b_rng, [1] gpdac_iob_en, [0] gpdac_b_en
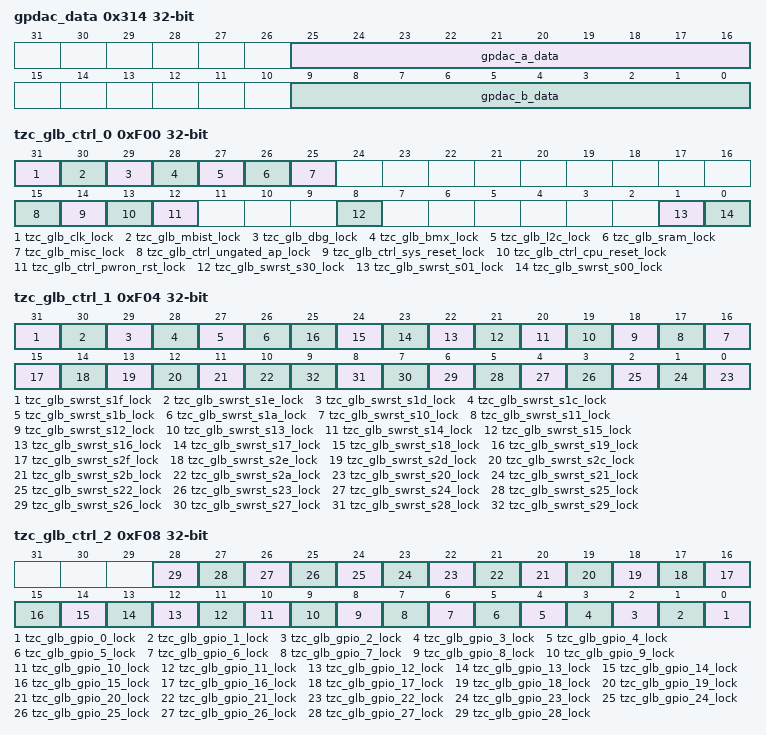
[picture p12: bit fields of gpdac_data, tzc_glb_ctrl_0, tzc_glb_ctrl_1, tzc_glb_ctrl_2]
0x314 gpdac_data
  [25:16] gpdac_a_data, [9:0] gpdac_b_data
0xF00 tzc_glb_ctrl_0 ro
  [31] tzc_glb_clk_lock, [30] tzc_glb_mbist_lock, [29] tzc_glb_dbg_lock, [28] tzc_glb_bmx_lock, [27] tzc_glb_l2c_lock, [26] tzc_glb_sram_lock, [25] tzc_glb_misc_lock, [15] tzc_glb_ctrl_ungated_ap_lock, [14] tzc_glb_ctrl_sys_reset_lock, [13] tzc_glb_ctrl_cpu_reset_lock, [12] tzc_glb_ctrl_pwron_rst_lock, [8] tzc_glb_swrst_s30_lock, [1] tzc_glb_swrst_s01_lock, [0] tzc_glb_swrst_s00_lock
0xF04 tzc_glb_ctrl_1 ro
  [31] tzc_glb_swrst_s1f_lock, [30] tzc_glb_swrst_s1e_lock, [29] tzc_glb_swrst_s1d_lock, [28] tzc_glb_swrst_s1c_lock, [27] tzc_glb_swrst_s1b_lock, [26] tzc_glb_swrst_s1a_lock, [n+6] tzc_glb_swrst_s{n}_lock (n=10..19), [15] tzc_glb_swrst_s2f_lock, [14] tzc_glb_swrst_s2e_lock, [13] tzc_glb_swrst_s2d_lock, [12] tzc_glb_swrst_s2c_lock, [11] tzc_glb_swrst_s2b_lock, [10] tzc_glb_swrst_s2a_lock, [n-20] tzc_glb_swrst_s{n}_lock (n=20..29)
0xF08 tzc_glb_ctrl_2 ro
  [n] tzc_glb_gpio_{n}_lock (n=0..28)
0xF0C tzc_glb_ctrl_3 — Reserved according to SDK.
